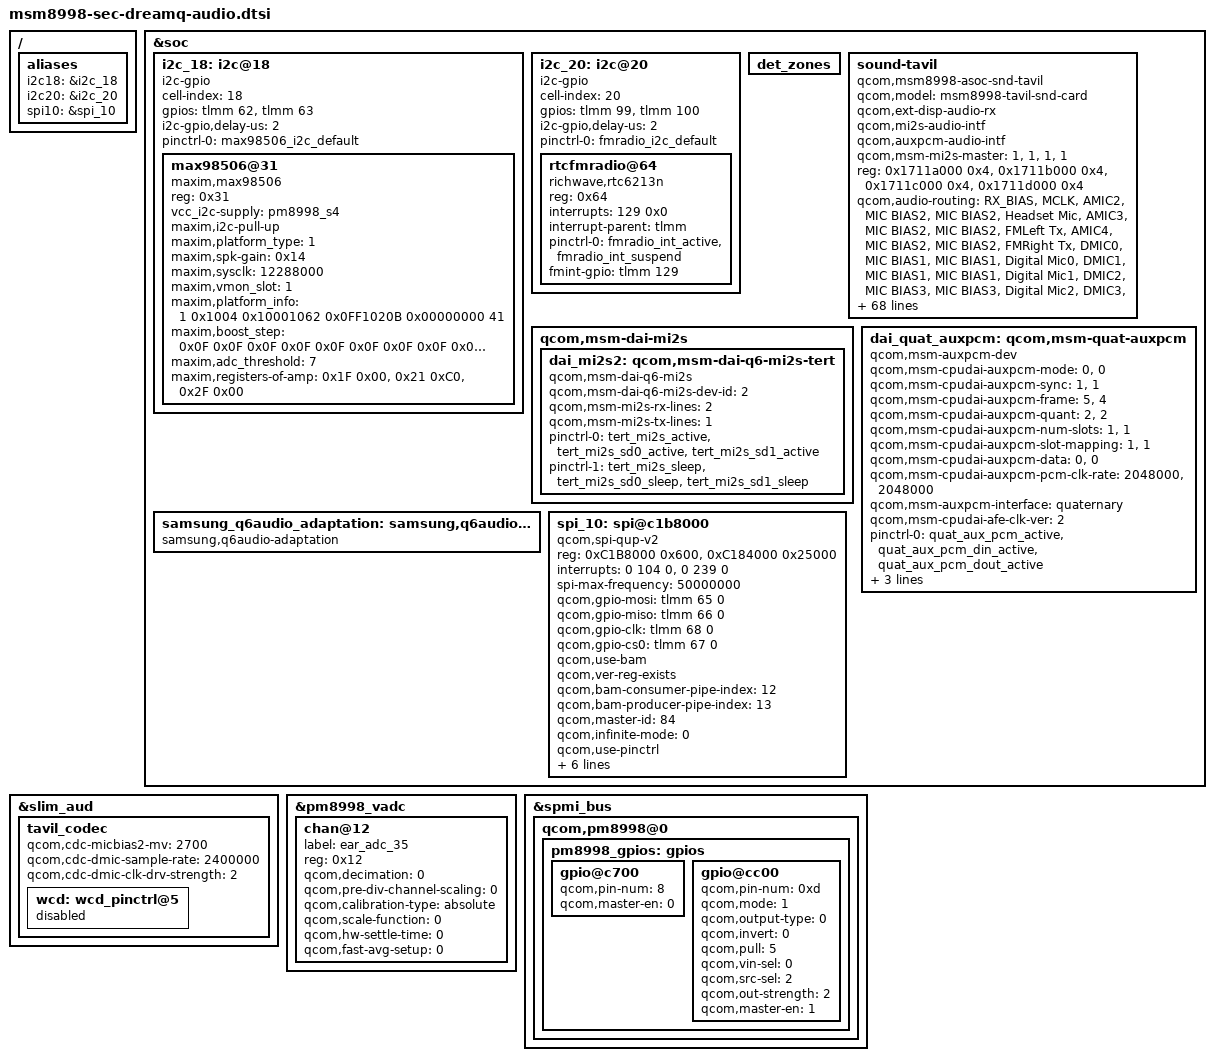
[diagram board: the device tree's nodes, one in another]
/*
 * Copyright (c) 2016-2017, The Linux Foundation. All rights reserved.
 *
 * This program is free software; you can redistribute it and/or modify
 * it under the terms of the GNU General Public License version 2 and
 * only version 2 as published by the Free Software Foundation.
 *
 * This program is distributed in the hope that it will be useful,
 * but WITHOUT ANY WARRANTY; without even the implied warranty of
 * MERCHANTABILITY or FITNESS FOR A PARTICULAR PURPOSE.  See the
 * GNU General Public License for more details.
 */

/{
	aliases {
		i2c18 = &i2c_18;
		i2c20 = &i2c_20;
		spi10 = &spi_10;
	};
};

&soc {
	i2c_18: i2c@18 { /* max98506 amp */
		cell-index = <18>;
		compatible = "i2c-gpio";
		gpios = <&tlmm 62 0 /* sda */
			&tlmm 63 0 /* scl */
		>;
		i2c-gpio,delay-us = <2>;
		#address-cells = <1>;
		#size-cells = <0>;
		pinctrl-names = "default";
		pinctrl-0 = <&max98506_i2c_default>;

		max98506@31 {
			compatible = "maxim,max98506";
			reg = <0x31>;
			vcc_i2c-supply = <&pm8998_s4>;
			maxim,i2c-pull-up;
			maxim,platform_type = <1>;
			maxim,spk-gain= <0x14>;
			maxim,sysclk = <12288000>;
			maxim,vmon_slot = <1>;
			maxim,platform_info = <1 0x1004 0x10001062 0x0FF1020B 0x00000000 41>;
			maxim,boost_step = <
				0x0F 0x0F 0x0F 0x0F
				0x0F 0x0F 0x0F 0x0F
				0x0F 0x0F 0x0F 0x0F
				0x0F 0x0F 0x02 0x00
			>;
			maxim,adc_threshold = <7>;
			maxim,registers-of-amp =
				<0x1F 0x00>,
				<0x21 0xC0>,
				<0x2F 0x00>;
		};
	};

	i2c_20: i2c@20{ /* FM Radio (Richwave) */
		cell-index = <20>;
		compatible = "i2c-gpio";

		gpios = <&tlmm 99 0 /* sda */
			&tlmm 100 0 /* scl */
		>;
		i2c-gpio,delay-us = <2>;
		#address-cells = <1>;
		#size-cells = <0>;
		status = "okay";
		pinctrl-names = "default";
		pinctrl-0 = <&fmradio_i2c_default>;

		rtcfmradio@64 {
			compatible = "richwave,rtc6213n", "rtc6213n";
			reg = <0x64>;
			interrupts = <129 0x0>;
			interrupt-parent = <&tlmm>;
			pinctrl-names = "default";
			pinctrl-0 = <&fmradio_int_active &fmradio_int_suspend>;
			fmint-gpio = <&tlmm 129 0>; /* FM_INT */
		};
	};

	det_zones: det_zones {
		#list-det-cells = <2>;
	};

	/delete-node/sound-9335;
	/delete-node/msm_cdc_pinctrl@75;
	/delete-node/audio_ext_clk ;
	/delete-node/msm_cdc_pinctrl@59;
	/delete-node/msm_cdc_pinctrl@60;

	sound-tavil {
		compatible = "qcom,msm8998-asoc-snd-tavil";
		qcom,model = "msm8998-tavil-snd-card";
		qcom,ext-disp-audio-rx;
		qcom,mi2s-audio-intf;
		qcom,auxpcm-audio-intf;
		qcom,msm-mi2s-master = <1>, <1>, <1>, <1>;

		reg = <0x1711a000 0x4>,
		      <0x1711b000 0x4>,
		      <0x1711c000 0x4>,
		      <0x1711d000 0x4>;
		reg-names = "lpaif_pri_mode_muxsel",
			    "lpaif_sec_mode_muxsel",
			    "lpaif_tert_mode_muxsel",
			    "lpaif_quat_mode_muxsel";

		qcom,audio-routing =
			"RX_BIAS", "MCLK",
			"AMIC2", "MIC BIAS2",
			"MIC BIAS2", "Headset Mic",
			"AMIC3", "MIC BIAS2",
			"MIC BIAS2", "FMLeft Tx",
			"AMIC4", "MIC BIAS2",
			"MIC BIAS2", "FMRight Tx",
			"DMIC0", "MIC BIAS1",
			"MIC BIAS1", "Digital Mic0",
			"DMIC1", "MIC BIAS1",
			"MIC BIAS1", "Digital Mic1",
			"DMIC2", "MIC BIAS3",
			"MIC BIAS3", "Digital Mic2",
			"DMIC3", "MIC BIAS3",
			"MIC BIAS3", "Digital Mic3",
			"DMIC4", "MIC BIAS4",
			"MIC BIAS4", "Digital Mic4",
			"DMIC5", "MIC BIAS4",
			"MIC BIAS4", "Digital Mic5";

		qcom,msm-mbhc-hphl-swh = <1>;
		qcom,msm-mbhc-gnd-swh = <1>;
		qcom,amux_channel = <18>;
		qcom,det_debounce_time_ms = <50>;
		qcom,earjack-read-vadc = <&pm8998_vadc>;
		qcom,tavil-mclk-clk-freq = <9600000>;

		asoc-platform = <&pcm0>, <&pcm1>, <&pcm2>, <&voip>, <&voice>,
				<&loopback>, <&compress>, <&hostless>,
				<&afe>, <&lsm>, <&routing>, <&cpe>, <&compr>,
				<&pcm_noirq>, <&trans_loopback>,
				<&samsung_q6audio_adaptation>;
		asoc-platform-names = "msm-pcm-dsp.0", "msm-pcm-dsp.1",
				"msm-pcm-dsp.2", "msm-voip-dsp",
				"msm-pcm-voice", "msm-pcm-loopback",
				"msm-compress-dsp", "msm-pcm-hostless",
				"msm-pcm-afe", "msm-lsm-client",
				"msm-pcm-routing", "msm-cpe-lsm",
				"msm-compr-dsp", "msm-pcm-dsp-noirq",
				"msm-transcode-loopback", "q6audio-adaptation";
		asoc-cpu = <&dai_hdmi>, <&dai_dp>,
				<&dai_mi2s0>, <&dai_mi2s1>,
				<&dai_mi2s2>, <&dai_mi2s3>,
				<&dai_pri_auxpcm>, <&dai_sec_auxpcm>,
				<&dai_tert_auxpcm>, <&dai_quat_auxpcm>,
				<&sb_0_rx>, <&sb_0_tx>, <&sb_1_rx>, <&sb_1_tx>,
				<&sb_2_rx>, <&sb_2_tx>, <&sb_3_rx>, <&sb_3_tx>,
				<&sb_4_rx>, <&sb_4_tx>, <&sb_5_tx>,
				<&afe_pcm_rx>, <&afe_pcm_tx>, <&afe_proxy_rx>,
				<&afe_proxy_tx>, <&incall_record_rx>,
				<&incall_record_tx>, <&incall_music_rx>,
				<&incall_music_2_rx>, <&sb_5_rx>, <&sb_6_rx>,
				<&usb_audio_rx>, <&usb_audio_tx>,
				<&dai_pri_tdm_rx_0>, <&dai_pri_tdm_tx_0>,
				<&dai_sec_tdm_rx_0>, <&dai_sec_tdm_tx_0>,
				<&dai_tert_tdm_rx_0>, <&dai_tert_tdm_tx_0>,
				<&dai_quat_tdm_rx_0>, <&dai_quat_tdm_tx_0>;
		asoc-cpu-names = "msm-dai-q6-hdmi.8",  "msm-dai-q6-dp.24608",
				"msm-dai-q6-mi2s.0", "msm-dai-q6-mi2s.1",
				"msm-dai-q6-mi2s.2", "msm-dai-q6-mi2s.3",
				"msm-dai-q6-auxpcm.1", "msm-dai-q6-auxpcm.2",
				"msm-dai-q6-auxpcm.3", "msm-dai-q6-auxpcm.4",
				"msm-dai-q6-dev.16384", "msm-dai-q6-dev.16385",
				"msm-dai-q6-dev.16386", "msm-dai-q6-dev.16387",
				"msm-dai-q6-dev.16388", "msm-dai-q6-dev.16389",
				"msm-dai-q6-dev.16390", "msm-dai-q6-dev.16391",
				"msm-dai-q6-dev.16392", "msm-dai-q6-dev.16393",
				"msm-dai-q6-dev.16395", "msm-dai-q6-dev.224",
				"msm-dai-q6-dev.225", "msm-dai-q6-dev.241",
				"msm-dai-q6-dev.240", "msm-dai-q6-dev.32771",
				"msm-dai-q6-dev.32772", "msm-dai-q6-dev.32773",
				"msm-dai-q6-dev.32770", "msm-dai-q6-dev.16394",
				"msm-dai-q6-dev.16396", "msm-dai-q6-dev.28672",
				"msm-dai-q6-dev.28673", "msm-dai-q6-tdm.36864",
				"msm-dai-q6-tdm.36865", "msm-dai-q6-tdm.36880",
				"msm-dai-q6-tdm.36881", "msm-dai-q6-tdm.36896",
				"msm-dai-q6-tdm.36897", "msm-dai-q6-tdm.36912",
				"msm-dai-q6-tdm.36913";
		asoc-codec = <&stub_codec>, <&ext_disp_audio_codec>;
		asoc-codec-names = "msm-stub-codec.1",
				   "msm-ext-disp-audio-codec-rx";

		det-zones-list = <&det_zones 0 2>,
				 <&det_zones 690 2>,
				 <&det_zones 691 1>,
				 <&det_zones 9999 1>;

		mbhc-button-thres = <&det_zones 13 63>,
				 <&det_zones 88 138>,
				 <&det_zones 138 138>,
				 <&det_zones 225 225>,
				 <&det_zones 450 450>,
				 <&det_zones 470 470>,
				 <&det_zones 470 470>,
				 <&det_zones 650 650>;

		/delete-property/qcom,wcn-btfm;
		/delete-property/qcom,us-euro-gpios;
		/delete-property/qcom,hph-en0-gpio;
		/delete-property/qcom,hph-en1-gpio;
		/delete-property/qcom,wsa-max-devs;
		/delete-property/qcom,wsa-devs;
		/delete-property/qcom,wsa-aux-dev-prefix;
		/delete-property/qcom,usbc-analog-en1_gpio;
		/delete-property/qcom,usbc-analog-en2_n_gpio;
	};

	qcom,msm-dai-mi2s {
		dai_mi2s2: qcom,msm-dai-q6-mi2s-tert {
			compatible = "qcom,msm-dai-q6-mi2s";
			qcom,msm-dai-q6-mi2s-dev-id = <2>;
			qcom,msm-mi2s-rx-lines = <2>;
			qcom,msm-mi2s-tx-lines = <1>;
			pinctrl-names = "default", "sleep";
			pinctrl-0 = <&tert_mi2s_active &tert_mi2s_sd0_active &tert_mi2s_sd1_active>;
			pinctrl-1 = <&tert_mi2s_sleep &tert_mi2s_sd0_sleep &tert_mi2s_sd1_sleep>;
		};
	};

	dai_quat_auxpcm: qcom,msm-quat-auxpcm {
		compatible = "qcom,msm-auxpcm-dev";
		qcom,msm-cpudai-auxpcm-mode = <0>, <0>;
		qcom,msm-cpudai-auxpcm-sync = <1>, <1>;
		qcom,msm-cpudai-auxpcm-frame = <5>, <4>;
		qcom,msm-cpudai-auxpcm-quant = <2>, <2>;
		qcom,msm-cpudai-auxpcm-num-slots = <1>, <1>;
		qcom,msm-cpudai-auxpcm-slot-mapping = <1>, <1>;
		qcom,msm-cpudai-auxpcm-data = <0>, <0>;
		qcom,msm-cpudai-auxpcm-pcm-clk-rate = <2048000>, <2048000>;
		qcom,msm-auxpcm-interface = "quaternary";
		qcom,msm-cpudai-afe-clk-ver = <2>;
		pinctrl-names = "default", "sleep";
		pinctrl-0 = <&quat_aux_pcm_active
			     &quat_aux_pcm_din_active
			     &quat_aux_pcm_dout_active>;
		pinctrl-1 = <&quat_aux_pcm_sleep
			     &quat_aux_pcm_din_sleep
			     &quat_aux_pcm_dout_sleep>;
 	};
	
	samsung_q6audio_adaptation: samsung,q6audio-adaptation {
		compatible = "samsung,q6audio-adaptation";
	};

	/delete-node/i2c_10;

	spi_10: spi@c1b8000 { /* BLSP2 QUP4 */
		compatible = "qcom,spi-qup-v2";
		#address-cells = <1>;
		#size-cells = <0>;
		reg-names = "spi_physical", "spi_bam_physical";
		reg = <0xC1B8000 0x600>,
		      <0xC184000 0x25000>;
		interrupt-names = "spi_irq", "spi_bam_irq";
		interrupts = <0 104 0>, <0 239 0>;

		spi-max-frequency = <50000000>;

		qcom,gpio-mosi = <&tlmm 65 0>;
		qcom,gpio-miso = <&tlmm 66 0>;
		qcom,gpio-clk  = <&tlmm 68 0>;
		qcom,gpio-cs0  = <&tlmm 67 0>;

		qcom,use-bam;
		qcom,ver-reg-exists;
		qcom,bam-consumer-pipe-index = <12>;
		qcom,bam-producer-pipe-index = <13>;
		qcom,master-id = <84>;
		qcom,infinite-mode = <0>;
		qcom,use-pinctrl;
		pinctrl-names = "spi_default", "spi_sleep";
		pinctrl-0 = <&spi_10_active &spi_10_cs0_active &spi_10_cs1_active>;
		pinctrl-1 = <&spi_10_sleep &spi_10_cs0_sleep &spi_10_cs1_sleep>;
		clock-names = "iface_clk", "core_clk";
		clocks = <&clock_gcc clk_gcc_blsp2_ahb_clk>,
			 <&clock_gcc clk_gcc_blsp2_qup4_spi_apps_clk>;
		status = "okay";
	};
};

/delete-node/&slim_qca;

&slim_aud {
	/delete-node/tasha_codec;

	tavil_codec {
		qcom,cdc-micbias2-mv = <2700>;
		qcom,cdc-dmic-sample-rate = <2400000>;
		qcom,cdc-dmic-clk-drv-strength = <2>;

		wcd: wcd_pinctrl@5 {
			status = "disabled";
		};
		/delete-node/msm_cdc_pinctrll;
		/delete-node/msm_cdc_pinctrlr;
		/delete-node/msm_cdc_pinctrl_us_euro_sw;
		/delete-node/msm_cdc_pinctrl_hph_en0;
		/delete-node/msm_cdc_pinctrl_hph_en1;
		/delete-node/swr_master;
	};
};

&pm8998_vadc {
	chan@12 {
		label = "ear_adc_35";
		reg = <0x12>;
		qcom,decimation = <0>;
		qcom,pre-div-channel-scaling = <0>;
		qcom,calibration-type = "absolute";
		qcom,scale-function = <0>;
		qcom,hw-settle-time = <0>;
		qcom,fast-avg-setup = <0>;
	};
};

&spmi_bus {
	qcom,pm8998@0 {
		pm8998_gpios: gpios {
			gpio@c700 { /* GPIO 8 EAR_ADC_3.5 */
				qcom,pin-num = <8>;
				qcom,master-en = <0>;
				status = "okay";
			};
			gpio@cc00 { /* GPIO 13 FM_SLEEP_CLK */
				qcom,pin-num = <0xd>;
				qcom,mode = <1>; /* Digital output */
				qcom,output-type = <0>;		/* CMOS logic */
				qcom,invert = <0>;		/* Output low initially */
				qcom,pull = <5>; /* No pull */
				qcom,vin-sel = <0>; /* VIN 0 */
				qcom,src-sel = <2>; /* Function 1 */
				qcom,out-strength = <2>;	/* Medium */
				qcom,master-en = <1>; /* Enable GPIO */
				status = "okay";
			};
		};
	};
};
